# PIC18F16Q20 register map
Vendor: Microchip
Registers are 8-bit, read-write, reset 0x0 unless marked. A register's access mark holds for its fields unless they carry their own. Addresses are absolute, and some are shared; only a register's first bit layout is shown; [hi:lo] are bit positions; {n}, {i} and the like mark numbered series.

## SFR
0x38 PRLOCK
  [0] PRLOCKED
0x39 MAINPR reset 0x7
  [2:0] PR
0x3A ISRPR reset 0x7
  [2:0] PR
{0x3A+i} DMA{i}PR reset 0x7 (i=1..4)
  [2:0] PR
0x3F SCANPR reset 0x7
  [2:0] PR
0x58 NVMCON0
  [0] GO
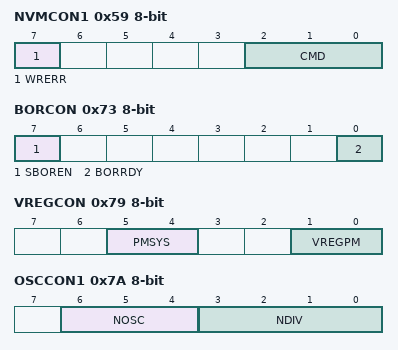
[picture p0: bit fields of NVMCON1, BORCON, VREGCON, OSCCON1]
0x59 NVMCON1
  [7] WRERR, [2:0] CMD
0x5A NVMLOCK
  [7:0] LOCK
0x5B NVMADRL reset not defined — (power-on value xxxxxxxx)
0x5C NVMADRH reset not defined — (power-on value xxxxxxxx)
0x5D NVMADRU reset not defined — (power-on value --xxxxxx)
  [5:0] NVMADRU
0x5E NVMDATL
0x5F NVMDATH
0x64 CRCOUTL
  [7:0] OUT
0x64 CRCSHFTL ro
  [7:0] SHIFT
0x64 CRCXORL
  [7:0] XOR
0x65 CRCOUTH
  [7:0] OUT
0x65 CRCSHFTH ro
  [7:0] SHIFT
0x65 CRCXORH
  [7:0] XOR
0x66 CRCOUTU
  [7:0] OUT
0x66 CRCSHFTU ro
  [7:0] SHIFT
0x66 CRCXORU
  [7:0] XOR
0x67 CRCOUTT
  [7:0] OUT
0x67 CRCSHFTT ro
  [7:0] SHIFT
0x67 CRCXORT
  [7:0] XOR
0x73 BORCON reset not defined — (power-on value 1------q)
  [7] SBOREN, [0] BORRDY ro
0x79 VREGCON reset not defined — (power-on value --qq--10)
  [5:4] PMSYS ro, [1:0] VREGPM
0x7A OSCCON1
  [6:4] NOSC, [3:0] NDIV
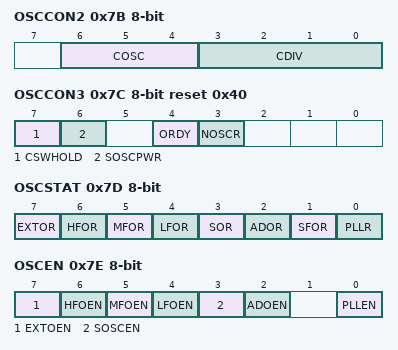
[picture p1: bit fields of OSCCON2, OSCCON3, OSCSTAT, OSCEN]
0x7B OSCCON2 ro
  [6:4] COSC, [3:0] CDIV
0x7C OSCCON3 reset 0x40
  [7] CSWHOLD, [6] SOSCPWR, [4] ORDY ro, [3] NOSCR ro
0x7D OSCSTAT ro
  [7] EXTOR, [6] HFOR, [5] MFOR, [4] LFOR, [3] SOR, [2] ADOR, [1] SFOR, [0] PLLR
0x7E OSCEN
  [7] EXTOEN, [6] HFOEN, [5] MFOEN, [4] LFOEN, [3] SOSCEN, [2] ADOEN, [0] PLLEN
0x7F OSCTUNE
  [5:0] TUN
0x80 OSCFRQ
  [3:0] FRQ
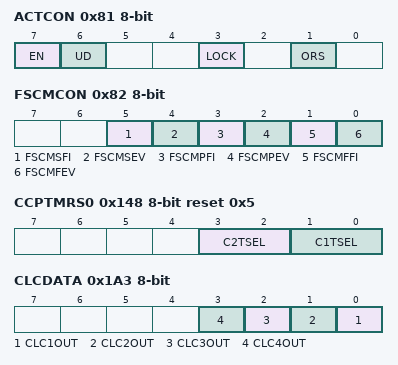
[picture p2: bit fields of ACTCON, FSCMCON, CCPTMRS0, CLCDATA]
0x81 ACTCON
  [7] EN, [6] UD, [3] LOCK ro, [1] ORS ro
0x82 FSCMCON
  [5] FSCMSFI, [4] FSCMSEV, [3] FSCMPFI, [2] FSCMPEV, [1] FSCMFFI, [0] FSCMFEV
0x12B TUCHAIN reset not defined — TMRU CHAIN SELECT REGISTER (power-on value -------u)
  [0] CH16AB
0x130 TU16ATMRL
  [7:0] TMRL
0x130 TU16ACRL ro
  [7:0] CRL
0x131 TU16ATMRH
  [7:0] TMRH
0x131 TU16ACRH ro
  [7:0] CRH
0x133 TU16ATMRT
  [7:0] TMRT
0x133 TU16ACRT ro
  [7:0] CRT
0x13E TU16BTMRL
  [7:0] TMRL
0x13E TU16BCRL ro
  [7:0] CRL
0x13F TU16BTMRH
  [7:0] TMRH
0x13F TU16BCRH ro
  [7:0] CRH
0x141 TU16BTMRT
  [7:0] TMRT
0x141 TU16BCRT ro
  [7:0] CRT
0x148 CCPTMRS0 reset 0x5
  [3:2] C2TSEL, [1:0] C1TSEL
0x1A3 CLCDATA
  [n-1] CLC{n}OUT (n=1..4)
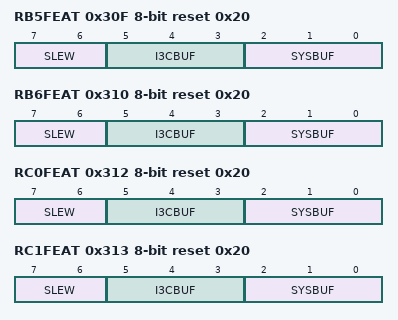
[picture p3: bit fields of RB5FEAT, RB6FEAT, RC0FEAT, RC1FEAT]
0x30F RB5FEAT reset 0x20
  [7:6] SLEW, [5:3] I3CBUF, [2:0] SYSBUF
0x310 RB6FEAT reset 0x20
  [7:6] SLEW, [5:3] I3CBUF, [2:0] SYSBUF
0x312 RC0FEAT reset 0x20
  [7:6] SLEW, [5:3] I3CBUF, [2:0] SYSBUF
0x313 RC1FEAT reset 0x20
  [7:6] SLEW, [5:3] I3CBUF, [2:0] SYSBUF
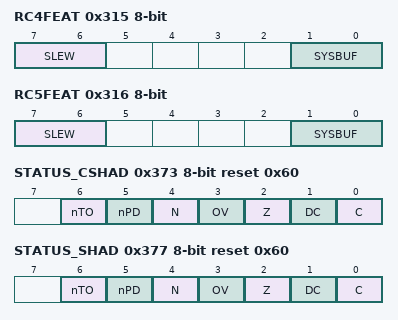
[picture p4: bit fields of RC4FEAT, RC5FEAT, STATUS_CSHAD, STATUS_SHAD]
0x315 RC4FEAT
  [7:6] SLEW, [1:0] SYSBUF
0x316 RC5FEAT
  [7:6] SLEW, [1:0] SYSBUF
0x351 PPSLOCK
  [0] PPSLOCKED
0x373 STATUS_CSHAD reset 0x60
  [6] nTO ro, [5] nPD ro, [4] N, [3] OV, [2] Z, [1] DC, [0] C
0x374 WREG_CSHAD reset not defined — (power-on value xxxxxxxx)
  [7:0] WREG
0x375 BSR_CSHAD
  [5:0] BSR
0x376 SHADCON
  [0] SHADLO
0x377 STATUS_SHAD reset 0x60
  [6] nTO ro, [5] nPD ro, [4] N, [3] OV, [2] Z, [1] DC, [0] C
0x378 WREG_SHAD reset not defined — (power-on value xxxxxxxx)
  [7:0] WREG
0x379 BSR_SHAD
  [5:0] BSR
0x37A PCLATH_SHAD
  [7:0] PCH
0x37B PCLATU_SHAD
  [4:0] PCU
{0x37C+2i} FSR{i}L_SHAD (i=0..2)
  [7:0] FSR{i}L
{0x37D+2i} FSR{i}H_SHAD (i=0..2)
  [5:0] FSR{i}H
0x382 PRODL_SHAD reset not defined — (power-on value xxxxxxxx)
  [7:0] PRODL
0x383 PRODH_SHAD reset not defined — (power-on value xxxxxxxx)
  [7:0] PRODH
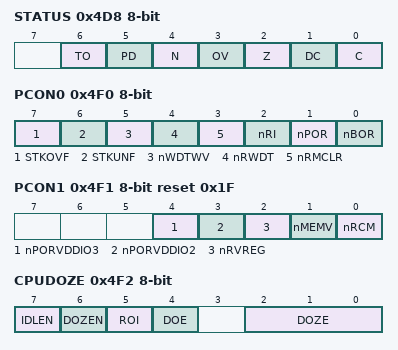
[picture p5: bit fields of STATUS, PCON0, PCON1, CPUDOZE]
0x4D8 STATUS reset not defined — (power-on value -xxxxxxx)
  [6] TO, [5] PD, [4] N, [3] OV, [2] Z, [1] DC, [0] C
0x4D9 FSR2L
0x4DA FSR2H
  [5:0] FSR2H
0x4DB PLUSW2 access not given reset not defined
0x4DC PREINC2 access not given reset not defined
0x4DD POSTDEC2 access not given reset not defined
0x4DE POSTINC2 access not given reset not defined
0x4DF INDF2 access not given reset not defined — (power-on value xxxxxxxx)
0x4E0 BSR
  [5:0] BSR
0x4E1 FSR1L
0x4E2 FSR1H
  [5:0] FSR1H
0x4E3 PLUSW1 access not given reset not defined
0x4E4 PREINC1 access not given reset not defined
0x4E5 POSTDEC1 access not given reset not defined
0x4E6 POSTINC1 access not given reset not defined
0x4E7 INDF1 access not given reset not defined — (power-on value xxxxxxxx)
0x4E8 WREG reset not defined — (power-on value xxxxxxxx)
0x4E9 FSR0L
0x4EA FSR0H
  [5:0] FSR0H
0x4EB PLUSW0 access not given reset not defined
0x4EC PREINC0 access not given reset not defined
0x4ED POSTDEC0 access not given reset not defined
0x4EE POSTINC0 access not given reset not defined
0x4EF INDF0 access not given reset not defined — (power-on value xxxxxxxx)
0x4F0 PCON0 reset not defined — (power-on value 0011110q)
  [7] STKOVF, [6] STKUNF, [5] nWDTWV, [4] nRWDT, [3] nRMCLR, [2] nRI, [1] nPOR, [0] nBOR
0x4F1 PCON1 reset 0x1F
  [4] nPORVDDIO3, [3] nPORVDDIO2, [2] nRVREG, [1] nMEMV, [0] nRCM
0x4F2 CPUDOZE
  [7] IDLEN, [6] DOZEN, [5] ROI, [4] DOE, [2:0] DOZE
0x4F3 PRODL reset not defined — (power-on value xxxxxxxx)
0x4F4 PRODH reset not defined — (power-on value xxxxxxxx)
0x4F5 TABLAT
0x4F6 TBLPTRL
0x4F7 TBLPTRH
0x4F8 TBLPTRU
  [5:0] TBLPTRU
0x4F9 PCL
  [7:0] PC
0x4FA PCLATH
  [7:0] PCH
0x4FB PCLATU
  [4:0] PCU
0x4FC STKPTR reset not defined — (power-on value -xxxxxxx)
  [6:0] STKPTR
0x4FD TOSL reset not defined — (power-on value xxxxxxxx)
0x4FE TOSH reset not defined — (power-on value xxxxxxxx)
0x4FF TOSU reset not defined — (power-on value ---xxxxx)
  [4:0] TOSU
